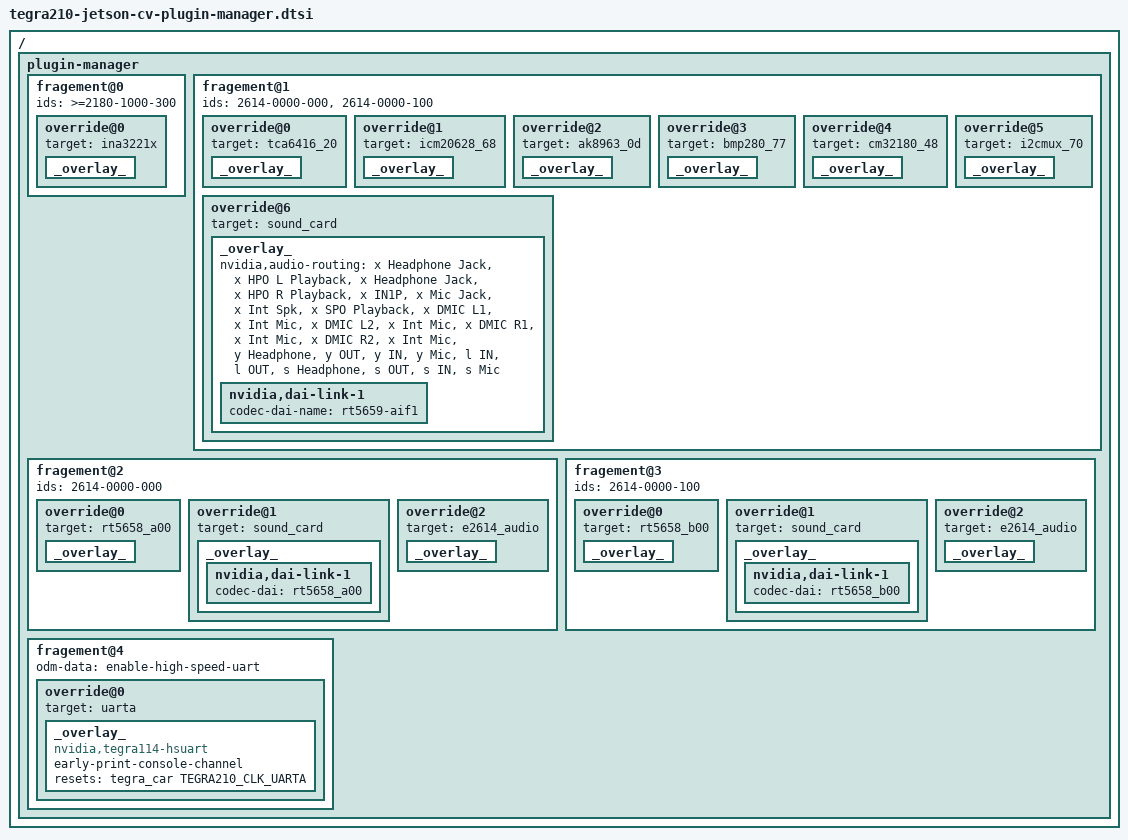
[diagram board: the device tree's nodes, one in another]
/*
 * Copyright (c) 2015-2017, NVIDIA CORPORATION.  All rights reserved.
 *
 * This program is free software; you can redistribute it and/or modify
 * it under the terms of the GNU General Public License as published by
 * the Free Software Foundation; version 2 of the License.
 *
 * This program is distributed in the hope that it will be useful, but WITHOUT
 * ANY WARRANTY; without even the implied warranty of MERCHANTABILITY or
 * FITNESS FOR A PARTICULAR PURPOSE.  See the GNU General Public License for
 * more details.
 *
 */

/ {
	plugin-manager {
		fragement@0 {
			ids = ">=2180-1000-300";
			override@0 {
				target = <&ina3221x>;
				_overlay_ {
					status = "okay";
				};
			};
		};

		fragement@1 {
			ids = "2614-0000-000", "2614-0000-100";
			override@0 {
				target = <&tca6416_20>;
				_overlay_ {
					status = "okay";
				};
			};

			override@1 {
				target = <&icm20628_68>;
				_overlay_ {
					status = "okay";
				};
			};

			override@2 {
				target = <&ak8963_0d>;
				_overlay_ {
					status = "okay";
				};
			};

			override@3 {
				target = <&bmp280_77>;
				_overlay_ {
					status = "okay";
				};
			};

			override@4 {
				target = <&cm32180_48>;
				_overlay_ {
					status = "okay";
				};
			};

			override@5 {
				target = <&i2cmux_70>;
				_overlay_ {
					status = "okay";
				};
			};

			override@6 {
				target = <&sound_card>;
				_overlay_ {
					nvidia,audio-routing =
						"x Headphone Jack",	"x HPO L Playback",
						"x Headphone Jack",	"x HPO R Playback",
						"x IN1P",		"x Mic Jack",
						"x Int Spk",		"x SPO Playback",
						"x DMIC L1",		"x Int Mic",
						"x DMIC L2",		"x Int Mic",
						"x DMIC R1",		"x Int Mic",
						"x DMIC R2",		"x Int Mic",
						"y Headphone",		"y OUT",
						"y IN",			"y Mic",
						"l IN",			"l OUT",
						"s Headphone",		"s OUT",
						"s IN",			"s Mic";
					nvidia,dai-link-1 {
						codec-dai-name = "rt5659-aif1";
					};
				};
			};
		};

		fragement@2 {
			ids = "2614-0000-000";
			override@0 {
				target = <&rt5658_a00>;
				_overlay_ {
					status = "okay";
				};
			};

			override@1 {
				target = <&sound_card>;
				_overlay_ {
					nvidia,dai-link-1 {
						codec-dai = <&rt5658_a00>;
					};
				};
			};

			override@2 {
				target = <&e2614_audio>;
				_overlay_ {
					status = "okay";
				};
			};
		};

		fragement@3 {
			ids = "2614-0000-100";
			override@0 {
				target = <&rt5658_b00>;
				_overlay_ {
					status = "okay";
				};
			};

			override@1 {
				target = <&sound_card>;
				_overlay_ {
					nvidia,dai-link-1 {
						codec-dai = <&rt5658_b00>;
					};
				};
			};

			override@2 {
				target = <&e2614_audio>;
				_overlay_ {
					status = "okay";
				};
			};
		};

		fragement@4 {
			odm-data = "enable-high-speed-uart";
			override@0 {
				target = <&uarta>;
				_overlay_ {
					compatible = "nvidia,tegra114-hsuart";
					early-print-console-channel;
					resets = <&tegra_car TEGRA210_CLK_UARTA>;
					reset-names = "serial";
				};
			};
		};
	};
};
